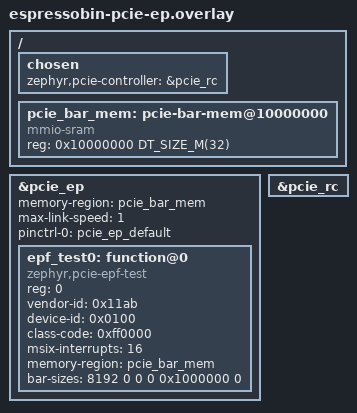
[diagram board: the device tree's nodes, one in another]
/*
 * ESPRESSObin: the Armada 3720 PCIe controller as endpoint on the
 * mini-PCIe slot.
 *
 * The slot is wired as a host slot (SoC TX on PERp/n 25/23, SoC RX on
 * PETp/n 33/31), so the link needs a crossover cable: host TX onto
 * PETp/n, PERp/n to host RX, ground. REFCLK and the supplies must NOT
 * be connected (ESPRESSObin wiki "Enabling ESPRESSObin board as PCIe
 * Endpoint"): both sides run on their own reference clock. PERST# from
 * the host onto pin 22 (PCA9306 to MPP2_3) is optional.
 */

#include <mem.h>

/ {
	chosen {
		/* root complex when "advk mode rc" is saved */
		zephyr,pcie-controller = &pcie_rc;
	};

	/*
	 * BAR backing store, outside Zephyr's RAM (ddr0 = 0..64 MiB) and
	 * TF-A (0x04000000..): nothing else uses it. Each BAR's inbound
	 * translation places it here, aligned to the BAR size (BAR0 8 KiB
	 * at +0, BAR4 16 MiB at +16 MiB), and the PCIe IO decode window is
	 * limited to it, so the host sees nothing else of DDR.
	 */
	pcie_bar_mem: pcie-bar-mem@10000000 {
		compatible = "mmio-sram";
		reg = <0x10000000 DT_SIZE_M(32)>;
	};
};


&pcie_ep {
	status = "okay";
	memory-region = <&pcie_bar_mem>;
	/* Gen1: the crossover link is clean only at 2.5 GT/s */
	max-link-speed = <1>;
	pinctrl-0 = <&pcie_ep_default>;
	pinctrl-names = "default";
	/*
	 * PERST# input; needs CONFIG_GPIO=y and the SB GPIO controller:
	 * perst-gpios = <&gpiosb 3 GPIO_ACTIVE_LOW>;
	 */

	epf_test0: function@0 {
		compatible = "zephyr,pcie-epf-test";
		reg = <0>;
		/*
		 * Marvell / A3720 default device ID, not in the pci_endpoint_test
		 * ID table: on the host
		 * echo "11ab 0100" > /sys/bus/pci/drivers/pci-endpoint-test/new_id
		 */
		vendor-id = <0x11ab>;
		device-id = <0x0100>;
		class-code = <0xff0000>;
		/* MSI-X table at register BAR + 0x40, PBA after it (16 x 16 B) */
		msix-interrupts = <16>;
		memory-region = <&pcie_bar_mem>;
		/*
		 * BAR0 and BAR4, 64-bit memory, sized through the LMI BAR
		 * configuration (powers of two); BAR2 (I/O) is switched off.
		 * BAR0 gets the registers, MSI-X table and DSN mailbox.
		 */
		bar-sizes = <8192 0 0 0 0x1000000 0>;
	};
};

/* The same controller as root complex, picked by "advk mode rc" */
&pcie_rc {
	status = "okay";
};
